AUTOSAR XML (schema 00051)
# SPDX-License-Identifier: LicenseRef-BSL-1.1
# Copyright (c) Craton; see /LICENSE
package /CratonShield  # Craton Shield Automotive Cybersecurity Runtime
package /CratonShield/ApplicationDesign
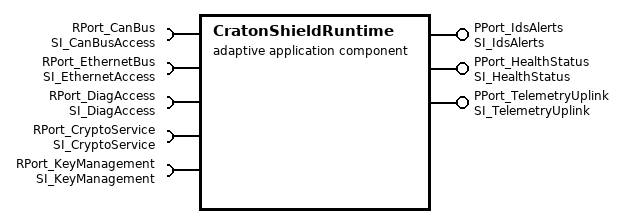
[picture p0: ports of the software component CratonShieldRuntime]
  adaptive application sw component type CratonShieldRuntime  # Craton Shield Runtime Cybersecurity Application
    provide port PPort_IdsAlerts: provided-interface=SI_IdsAlerts
    provide port PPort_HealthStatus: provided-interface=SI_HealthStatus
    provide port PPort_TelemetryUplink: provided-interface=SI_TelemetryUplink
    5 x require port:
      RPort_CanBus: required-interface=SI_CanBusAccess
      RPort_EthernetBus: required-interface=SI_EthernetAccess
      RPort_DiagAccess: required-interface=SI_DiagAccess
      RPort_CryptoService: required-interface=SI_CryptoService
      RPort_KeyManagement: required-interface=SI_KeyManagement
package /CratonShield/ServiceInterfaces
  8 x service interface:
    SI_IdsAlerts
      service interface namespace cratonshield
      events:
        data SecurityAlert: type=DT_SecurityAlert
      methods:
        operation GetAlertHistory
          arg maxEntries: type=DT_UInt32, direction=IN
    SI_HealthStatus
      field PlatformHealth: type=DT_PlatformHealth, has-getter=true, has-notifier=true
    SI_TelemetryUplink
      methods:
        operation SendTelemetryBatch
          arg encryptedPayload: type=DT_ByteArray, direction=IN
    SI_CanBusAccess
      events:
        data CanFrame: type=DT_CanFrame
    SI_EthernetAccess
      events:
        data EthernetPacket: type=DT_EthernetPacket
    SI_DiagAccess
      methods:
        operation ProcessUdsRequest
          arg request: type=DT_ByteArray, direction=IN
    SI_CryptoService
      methods:
        5 x operation:
          Encrypt
          Decrypt
          Sign
          Verify
          Hash
    SI_KeyManagement
      methods:
        4 x operation:
          ProvisionKey
          RotateKey
          RevokeKey
          GetKeyStatus
package /CratonShield/DataTypes
  6 x impl type:
    DT_UInt32: category=VALUE
    DT_ByteArray: category=VECTOR
    DT_SecurityAlert: category=STRUCTURE
      6 x element:
        alertId
        severity
        busType
        sourceId
        payloadHash
        timestampUs
    DT_PlatformHealth: category=STRUCTURE
      13 x element:
        crypto
        keyManager
        secureBoot
        canMonitor
        ethMonitor
        idsEngine
        firewall
        diagGateway
        otaValidator
        anomaly
        integrity
        telemetry
        policyEngine
    DT_CanFrame: category=STRUCTURE
      6 x element:
        arbitrationId
        dlc
        data
        isExtended
        isFd
        timestampUs
    DT_EthernetPacket: category=STRUCTURE
      5 x element:
        srcMac
        dstMac
        vlanId
        ethertype
        payload
package /CratonShield/ExecutionManifest
  executable CratonShieldExe: category=APPLICATION_LEVEL, minimum-timer-granularity-value=0.001
    root sw component prototype CratonShieldRuntimeInstance: application-type=CratonShieldRuntime
  process CratonShieldProcess: executable=CratonShieldExe, state-dependent-startup-config{function-group-state=MachineState.Running, startup-config={scheduling-policy=SCHED_FIFO, scheduling-priority=90, resource-group=SecurityCritical}}
  function group MachineState
    4 x function group state:
      Off
      Verify
      Running
      Shutdown
package /CratonShield/ResourceGroups
  resource group SecurityCritical: cpu-usage=80, mem-usage=67108864
package /CratonShield/MachineMapping
  machine design VehicleECU
    ethernet communication connector EthConn_Vehicle
    processor CortexA53
      4 x processor core:
        Core{0..3}
